# S32K312_M7 register map
Vendor: NXP Semiconductors; File version: 1.4
CPU: CM7 r0p1, little endian, MPU, FPU, VTOR, 4 interrupt priority bits
Registers are 32-bit, read-write, reset 0x0 unless marked. A register's access mark holds for its fields unless they carry their own. Offsets are from the block's base; [hi:lo] are bit positions; {n}, {i} and the like mark numbered series; 'fields as' and 'values as' point back to an identical list.

## STCU — STCU2
Base 0x403A0000
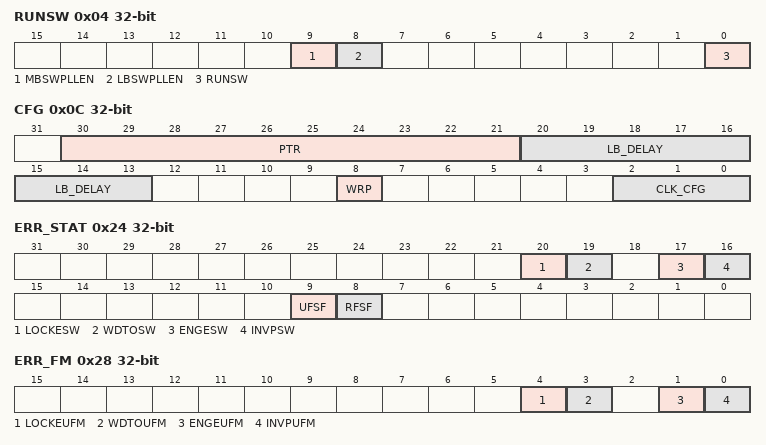
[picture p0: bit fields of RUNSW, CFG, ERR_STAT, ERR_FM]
0x04 RUNSW — STCU2 Run Software
  [9] MBSWPLLEN — Online MBIST with PLL Enabled
    0=A14 (Online MBIST is executed without using the on-chip PLL.); 1=A15 (Online MBIST is executed using the PLL configuration provided by software. STCU2 does not take the PLL control but monitors the PLL lock signal to check if PLL is working correctly.)
  [8] LBSWPLLEN — Online LBIST with PLL Enabled
    0=A12 (Online LBIST is executed without using the on-chip PLL.); 1=A13 (Online LBIST is executed using the PLL configuration provided by the software. STCU2 does not take the PLL control but monitors the PLL lock signal to check if PLL is working correctly.)
  [0] RUNSW — The RUNSW bit is automatically cleared by STCU2 when the online self-testing procedure is complete.
    0=A8 (Idle); 1=A9 (Online self-testing procedure is running)
0x08 SKC wo — STCU2 SK Code
0x0C CFG — STCU2 Configuration
  [30:21] PTR — First LBIST or MBIST pointer PTR defines the logical pointer to the first LBIST or MBIST to be scheduled when the self-testing procedure is enabled
  [20:13] LB_DELAY — Delay LBIST run LB_DELAY defines the delay between the LBIST starts when more than a single LBIST is selected to be executed concurrently with the purpose of smoothing the power consumption transient
  [8] WRP — Write Protection 0: Specific STCU2 registers can be written through IPS bus interface 1: STCU2 registers cannot be written through IPS, preventing any user application write operation
  [2:0] CLK_CFG — Logic, Memory BIST, and STCU2 CORE_CLK configuration CLK_CFG defines the ratio between the sys_clk and the internal clock used to program both the LBIST and the MBIST and the STCU2 CORE_CLK
    {v}=sys_clk{v+1} (v=0..7)
0x14 WDG reset 0xFFFF — STCU2 Watchdog Granularity
  [31:0] WDGEOC — Watchdog End of Count Timer This value has to be set to define the time budget related to the online self-test execution and check that everything is correctly working within this slot of time
0x24 ERR_STAT — STCU2 Error
  [20] LOCKESW ro — Online LOCK error You can always read this field
    0=LOCK (In case PLL is enabled, it is correctly locked during the self-test sequence); 1=UNLOCK (When the PLL is enabled, this flag highlights that there has been an unexpected PLL unlock(loss-of-lock) event during the online self-test sequence execution. The online self-test run is stopped and the status of the currently running LBISTs or MBISTs is saved in the related registers. The LOCK signal is monitored during the LBIST run when RUNSW[LBSWPLLEN] is set and/or during the MBIST run when RUNSW[MBSWPLLEN] = 1.)
  [19] WDTOSW ro — Online watchdog timeout You can always read this field
    0=COMPLETED (LBIST and MBIST time slots completed within the assigned watchdog time.); 1=NOT_COMPLETED (LBIST and MBIST time slots not completed within the assigned watchdog time or there are internal mismatches among End of Execution signals.)
  [17] ENGESW ro — Online engine error You can always read this field
    0=VALID (Valid engine execution); 1=INVALID (Invalid engine execution. The error conditions that set this bit are FSM, protocol error, and so on.)
  [16] INVPSW ro — Online invalid pointer You can always read this field
    0=VALID (Valid linked pointer list); 1=INVALID (Invalid linked pointer list. The following conditions set this bit: Initial LBIST or MBIST pointer is out of range; LBIST is selected when MBIST is concurrently running or vice versa; Error in the LBIST/MBIST linking (execution generates an infinite loop).)
  [9] UFSF — Unrecoverable Faults Status Flag This flag reports the global status of the Unrecoverable Faults(UF)
    0=NO_ERROR (No errors that trigger the UF condition.); 1=ERROR (There are errors that trigger the UF condition.)
  [8] RFSF — Recoverable Faults Status Flag This flag reports the global status of the Recoverable Fault (RF)
    0=NO_ERROR (No errors that trigger the Recoverable Faults condition); 1=ERROR (There are errors that trigger the Recoverable Faults condition)
0x28 ERR_FM — STCU2 Error FM
  [4] LOCKEUFM — PLL LOCK Unrecoverable Fault Mapping
    0=RECOVERABLE (Recoverable Fault Mapping); 1=UNRECOVERABLE (Unrecoverable Fault Mapping)
  [3] WDTOUFM — Watchdog Timeout Unrecoverable Fault Mapping
    values as LOCKEUFM
  [1] ENGEUFM — Engine Error Unrecoverable Fault Mapping
    values as LOCKEUFM
  [0] INVPUFM — Invalid Pointer Unrecoverable Fault Mapping
    0=RECOVERABLE (Recoverable Fault Mapping); 1=UNRECOVERABLE (Unrecoverable Mapping)
0x4C LBSSW0 ro — STCU2 Online LBIST Status
  [0] LBSSW0
    0=FAIL (Failed LBIST execution); 1=SUCCESS (Successful LBIST execution)
0x5C LBESW0 ro — STCU2 Online LBIST End Flag
  [0] LBESW0 — LBESW
    0=INCOMPLETE (LBIST execution not yet completed); 1=COMPLETE (LBIST execution finished)
0x6C LBRMSW0 — STCU2 Online LBIST Reset Management
  [0] LBRMSW0 — LBRMSW
    0=FUNCTIONAL (Dedicated functional reset is pulsed at the end of LBIST run); 1=GLOBAL (Global functional reset is pulsed at the end of LBIST run)
0x7C LBUFM0 — STCU2 Online LBIST Unrecoverable FM
  [0] LBUFM0 — LBIST Unrecoverable Fault Mapping
    0=RECOVERABLE (Recoverable Fault mapping); 1=UNRECOVERABLE (Unrecoverable Fault mapping)
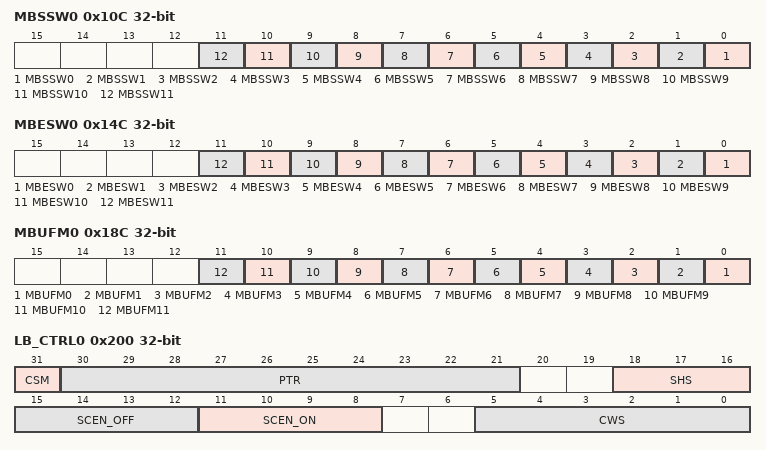
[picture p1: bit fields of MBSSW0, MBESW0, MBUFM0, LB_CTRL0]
0x10C MBSSW0 ro — STCU2 Online MBIST Status
  [all] fields
    0=FAIL (Failed MBIST execution); 1=PASS (No fault detected during the MBIST execution)
  [n] MBSSW{n} (n=0..11) — MBSSW
0x14C MBESW0 ro — STCU2 Online MBIST End Flag
  [all] fields
    0=ONGOING (MBIST execution still ongoing); 1=FINISHED (MBIST execution finished)
  [n] MBESW{n} (n=0..11) — Online end status of MBISTn (where n = 11:0).
0x18C MBUFM0 — STCU2 MBIST Unrecoverable FM
  [all] fields
    0=RECOVERABLE (Recoverable fault mapping); 1=UNRECOVERABLE (Unrecoverable fault mapping)
  [n] MBUFM{n} (n=0..11) — MBESW
0x200 LB_CTRL0 — STCU2 LBIST Control
  [31] CSM — Concurrent/sequential mode The next LBIST is scheduled concurrently to the current one if the CSM bit is set to 1; otherwise, it is scheduled sequentially to the completion of the current LBIST execution
    0=SEQUENTIAL (Sequential mode); 1=CONCURRENT (Concurrent mode)
  [30:21] PTR — Next LBIST or MBIST pointer PTR defines the logical pointer to the next LBIST or MBIST to be scheduled
  [18:16] SHS — Shift speed SHS defines the shift speed
    0=FULL (Shift at full rate (BIST clock).); {v}=SHIF_{v+1} (Shift at 1/{v+1} rate (BIST clock).) (v=1..7)
  [15:12] SCEN_OFF — Scan enable OFF SCEN_OFF information is used to configure the lbist controller hardware to generate off_cycles, delay cycles during the scan enable off transition
    0=DELAY_0 (0 delay cycles); 1=DELAY_1 (1 delay cycle); {v}=DELAY_{v} ({v} delay cycles) (v=2..15)
  [11:8] SCEN_ON — Scan enable ON SCEN_ON information is used to configure the lbist controller hardware to generate on_cycles, delay cycles during the scan enable on transition, SCEN_ON delay register value must be programmed to a value >=1
    values as SCEN_OFF
  [5:0] CWS — Capture window size CWS defines the capture window size.
    0=ILLGEAL (Illegal); 1=LEGAL_1 (Controller waits 1 shift cycle for capture to finish.); {v}=LEGAL_{v} (Controller waits {v} shift cycles for capture to finish.) (v=2..7)
0x204 LB_PCS0 — STCU2 LBIST PC Stop
  [25:0] PCS
0x220 LB_MISRELSW0 reset 0xFFFFFFFF — STCU2 Online LBIST MISR Expected Low
  [31:0] MISRESWx — Online MISR expected low bits This field defines 32 bits of the expected MISR.
0x224 LB_MISREHSW0 reset 0xFFFFFFFF — STCU2 Online LBIST MISR Expected High
  [31:0] MISRESWx — Online MISR Expected High Bits This field defines the 32 bits of the expected MISR.
0x228 LB_MISRRLSW0 ro — STCU2 Online LBIST MISR Read Low
  [31:0] MISRRSWx
0x22C LB_MISRRHSW0 ro — STCU2 Online LBIST MISR Read High
  [31:0] MISRRSWx
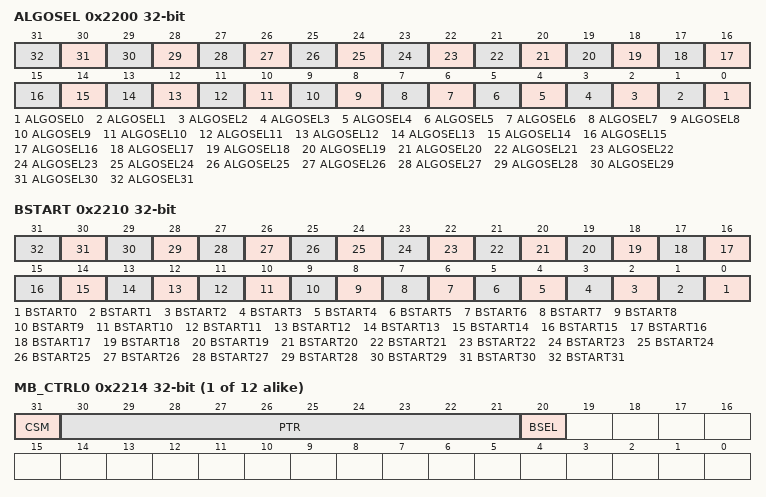
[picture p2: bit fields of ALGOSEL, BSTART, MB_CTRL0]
0x2200 ALGOSEL — STCU2 Algorithm Select
  [n] ALGOSEL{n} (n=0..31) — Algorithm Select
0x220C STGGR — STCU2 MBIST Stagger
  [31:0] STAG
0x2210 BSTART — STCU2 BIST Start
  [n] BSTART{n} (n=0..31) — BIST Start
{0x2214+4i} MB_CTRL{i} (i=0..11) — STCU2 MBIST Control
  [31] CSM
    values as LB_CTRL0.CSM
  [30:21] PTR
  [20] BSEL wo
    0=RUN (Selected BIST is not selected for execution.); 1=NO_RUN (Selected BIST is selected for execution.)
